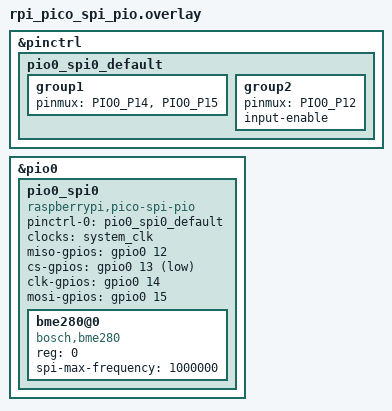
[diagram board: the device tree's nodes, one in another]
&pinctrl {
	pio0_spi0_default: pio0_spi0_default {
		/* gpio 13 is used for chip select, not assigned to the PIO */
		group1 {
			pinmux = <PIO0_P14>, <PIO0_P15>;
		};
		group2 {
			pinmux = <PIO0_P12>;
			input-enable;
		};
	};
};

&pio0 {
	status = "okay";

	pio0_spi0: pio0_spi0 {
		pinctrl-0 = <&pio0_spi0_default>;
		pinctrl-names = "default";

		compatible = "raspberrypi,pico-spi-pio";
		status = "okay";
		#address-cells = <1>;
		#size-cells = <0>;
		clocks = < &system_clk >;
		miso-gpios = <&gpio0 12 0>;
		cs-gpios = <&gpio0 13 GPIO_ACTIVE_LOW>;
		clk-gpios = <&gpio0 14 GPIO_ACTIVE_HIGH>;
		mosi-gpios = <&gpio0 15 GPIO_ACTIVE_HIGH>;
		bme280@0 {
			compatible = "bosch,bme280";
			reg = <0>;
			spi-max-frequency = <1000000>; /* conservatively set to 1MHz */
		};
	};
};
